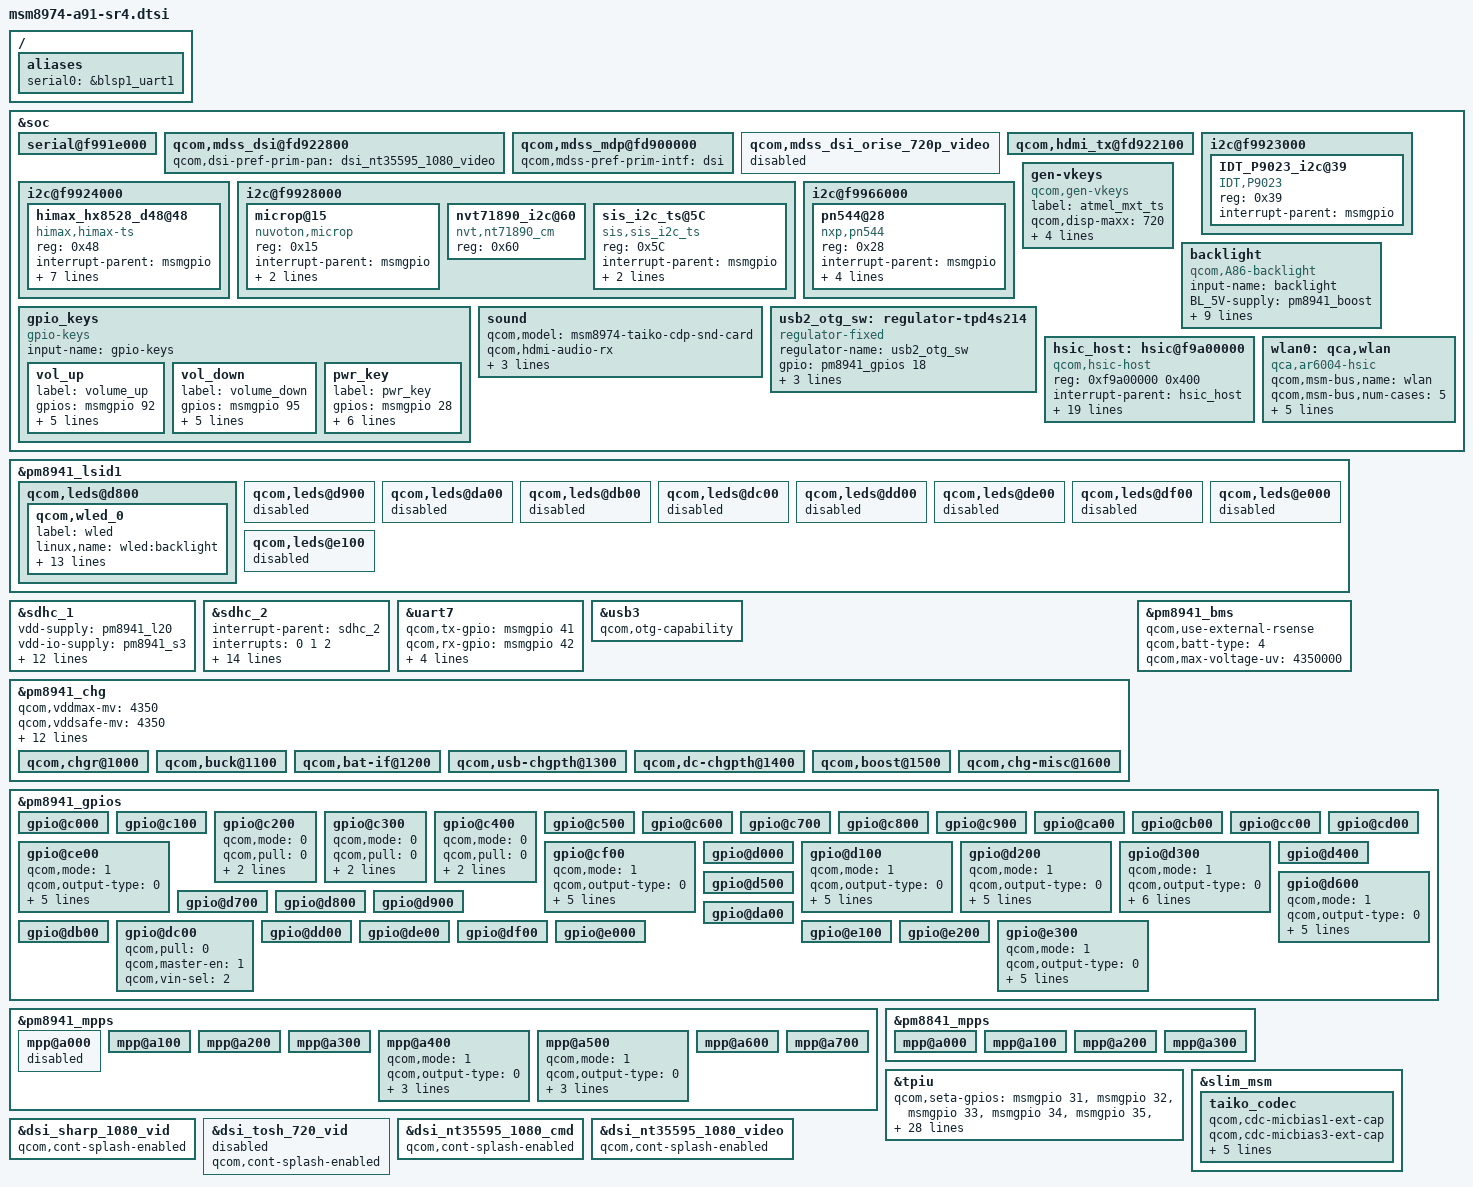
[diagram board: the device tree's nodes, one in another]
/* Copyright (c) 2012-2014, The Linux Foundation. All rights reserved.
 *
 * This program is free software; you can redistribute it and/or modify
 * it under the terms of the GNU General Public License version 2 and
 * only version 2 as published by the Free Software Foundation.
 *
 * This program is distributed in the hope that it will be useful,
 * but WITHOUT ANY WARRANTY; without even the implied warranty of
 * MERCHANTABILITY or FITNESS FOR A PARTICULAR PURPOSE.  See the
 * GNU General Public License for more details.
 */

//+++ ASUS_BSP : modify from msm8974-cdp.dtsi

#include "asus-common.dtsi"

/ {
	aliases {
		serial0 = &blsp1_uart1;
	};
};

&soc {
	serial@f991e000 {
		status = "ok";
	};

	qcom,mdss_dsi@fd922800 {
		qcom,dsi-pref-prim-pan = <&dsi_sharp_1080_vid>; // Add for ASUS Display driver 
		qcom,dsi-pref-prim-pan = <&dsi_nt35595_1080_cmd>; // Add for ASUS Innolux command mode driver 
        qcom,dsi-pref-prim-pan = <&dsi_nt35595_1080_video>;// Add for ASUS Innolux video mode driver 
	};

	qcom,mdss_mdp@fd900000 {
		qcom,mdss-pref-prim-intf = "dsi";
	};

	qcom,mdss_dsi_orise_720p_video {
		status = "disable";
	};

	qcom,hdmi_tx@fd922100 {
		status = "ok";
	};

// +++.....................................................I2C bus part....................................................+++//
//+++ ASUS BSP Eason......."BLSP1 : Wireless charger"
	i2c@f9923000 {
		IDT_P9023_i2c@39 {
			compatible = "IDT,P9023";
			reg = <0x39>;
			interrupt-parent = <&msmgpio>;
		};
	};
//--- ASUS BSP Eason......."BLSP1 : Wireless charger"

// +++ ASUS_BSP : add for ASUS touch 
	i2c@f9924000 {
		himax_hx8528_d48@48 {
			compatible = "himax,himax-ts";
			reg = <0x48>;
			interrupt-parent = <&msmgpio>;
			interrupts = <0 0x2>;
			vdd_ana-supply = <&pm8941_l23>;
			vcc_i2c-supply = <&pm8941_lvs1>;
			himax,reset-gpio = <&msmgpio 60 0x00>;
			himax,irq-gpio = <&msmgpio 0 0x00>;
			himax,pcb-id0 = <&msmgpio 69 0x00>;
			himax,pcb-id1 = <&msmgpio 90 0x00>;
		};
	};
// --- ASUS_BSP : add for ASUS touch 

// +++ ASUS BSP......."BLSP6 : Pad bus"
i2c@f9928000 {
		//+++ ASUS_BSP Eason +++
		microp@15 {
			compatible = "nuvoton,microp";
			reg = <0x15>;
			interrupt-parent = <&msmgpio>;
			interrupts = <9 0x2>;
			microp,irq-gpio = <&msmgpio 9 0x00>;
		};
		//--- ASUS_BSP Eason ---

		// ASUS_BSP +++ Louis, "Pad TCON control driver"
		nvt71890_i2c@60 {
			compatible = "nvt,nt71890_cm";
			reg = <0x60>;
		};
		// ASUS_BSP --- Louis, "Pad TCON control driver"

		// ASUS_BSP +++ SiS9257 Touch
		sis_i2c_ts@5C {
			compatible = "sis,sis_i2c_ts";
			reg = <0x5C>;
			interrupt-parent = <&msmgpio>;
			interrupts = <9 0x2>;
			sis_i2c_ts,irq-gpio = <&msmgpio 9 0x00>;
		};
		// ASUS_BSP --- SiS9257 Touch
	};
//--- ASUS BSP......."BLSP6 : Pad bus"

	//+++ ASUS BSP......."BLSP10 : NFC"
	i2c@f9966000 {
		//+++Porting NFC's kernel+++
		pn544@28 {
			//compatible = "nxp,nxp_pn544";
			compatible = "nxp,pn544";
			reg = <0x28>;
			interrupt-parent = <&msmgpio>;
			interrupts = <59 0x2>;
			nxp,irq-gpio = <&msmgpio 59 0x00>;
			nxp,nfc-ven = <&msmgpio 79 0x00>;
			nxp,download-gpio = <&pm8941_gpios 24 0x00>;
		};
		//---Porting NFC's kernel---
	};
	//--- ASUS BSP......."BLSP10 : NFC"

//---.....................................................I2C bus part....................................................---//

	gen-vkeys {
		compatible = "qcom,gen-vkeys";
		label = "atmel_mxt_ts";
		qcom,disp-maxx = <720>;
		qcom,disp-maxy = <1280>;
		qcom,panel-maxx = <760>;
		qcom,panel-maxy = <1424>;
		qcom,key-codes = <158 139 102 217>;
	};

//ASUS BSP freddy++ set gpio_keys	
	gpio_keys {
		compatible = "gpio-keys";
		input-name = "gpio-keys";

		vol_up {
			label = "volume_up";
			gpios = <&msmgpio 92 0x00>;
			interrupt-parent = <&msmgpio>;
			interrupts = <92 0x2>; 
			linux,input-type = <1>;
			linux,code = <115>;
			//gpio-key,wakeup;
			debounce-interval = <1>;
		};

		vol_down {
			label = "volume_down";
			gpios = <&msmgpio 95 0>;
			interrupt-parent = <&msmgpio>;
			interrupts = <95 0x2>;
			linux,input-type = <1>;
			linux,code = <114>;
			//gpio-key,wakeup;
			debounce-interval = <1>;
		};

	        pwr_key {
	            label = "pwr_key";
	            gpios = <&msmgpio 28 0x00>;
	            interrupt-parent = <&msmgpio>;
	            interrupts = <28 0x2>;
	            linux,input-type = <1>;
	            linux,code = <116>;
	            gpio-key,wakeup;
	            debounce-interval = <1>;
	        };
	};

	//ASUS BSP Jacob kung +++
	backlight {
		compatible = "qcom,A86-backlight";
		input-name = "backlight";
		BL_5V-supply = <&pm8941_boost>;
		pan-backlight-levels = <1 255>;
		bl-tout-defau-levels = <7 58>;
		normod-bl-param = <17 151 412>;
		outmod-bl-param = <58 255 340>;
		autmod-bl-param = <17 255 272>;
		factory-bl-param = <0 255 272>;
		pad-normod-bl-param = <0 250 240>;
		pad-outmod-bl-param = <33 255 557>;
		pad-autmod-bl-param = <9 255 448>;
		status = "okay";
	};
	//ASUS BSP Jacob kung +++
	sound {
		qcom,model = "msm8974-taiko-cdp-snd-card";
		qcom,hdmi-audio-rx;
		qcom,us-euro-gpios = <&pm8941_gpios 20 0>;
		qcom,cdc-micbias2-headset-only;
		qcom,mbhc-audio-jack-type = "6-pole-jack";
	};

	usb2_otg_sw: regulator-tpd4s214 {
		compatible = "regulator-fixed";
		regulator-name = "usb2_otg_sw";
		gpio = <&pm8941_gpios 18 0>;
		parent-supply = <&pm8941_boost>;
		startup-delay-us = <17000>;
		enable-active-high;
	};

	hsic_host: hsic@f9a00000 {
		compatible = "qcom,hsic-host";
		reg = <0xf9a00000 0x400>;
		#address-cells = <0>;
		interrupt-parent = <&hsic_host>;
		interrupts = <0 1 2>;
		#interrupt-cells = <1>;
		interrupt-map-mask = <0xffffffff>;
		interrupt-map = <0 &intc 0 136 0
			1 &intc 0 148 0
			2 &msmgpio 144 0x8>;
		interrupt-names = "core_irq", "async_irq", "wakeup";
		hsic_vdd_dig-supply = <&pm8841_s2_corner>;
		HSIC_GDSC-supply = <&gdsc_usb_hsic>;
		hsic,strobe-gpio = <&msmgpio 144 0x00>;
		hsic,data-gpio = <&msmgpio 145 0x00>;
		hsic,resume-gpio = <&msmgpio 80 0x00>;
		hsic,ignore-cal-pad-config;
		hsic,strobe-pad-offset = <0x2050>;
		hsic,data-pad-offset = <0x2054>;
		qcom,phy-susp-sof-workaround;
		hsic,vdd-voltage-level = <1 5 7>;

		qcom,msm-bus,name = "hsic";
		qcom,msm-bus,num-cases = <2>;
		qcom,msm-bus,num-paths = <1>;
		qcom,msm-bus,vectors-KBps =
				<85 512 0 0>,
				<85 512 40000 160000>;
        };

	wlan0: qca,wlan {
		compatible = "qca,ar6004-hsic";
		qcom,msm-bus,name = "wlan";
		qcom,msm-bus,num-cases = <5>;
		qcom,msm-bus,active-only = <0>;
		qcom,msm-bus,num-paths = <1>;
		qcom,msm-bus,vectors-KBps =
				<85 512 0 0>,
				<85 512 40000 160000>,
				<85 512 40000 320000>,
				<85 512 40000 480000>,
				<85 512 40000 800000>;
	};
};

&pm8941_lsid1 {
	qcom,leds@d800 {
		status = "okay";
		qcom,wled_0 {
			label = "wled";
			linux,name = "wled:backlight";
			linux,default-trigger = "bkl-trigger";
			qcom,cs-out-en;
			qcom,op-fdbck = <1>;
			qcom,default-state = "on";
			qcom,max-current = <20>;
			qcom,ctrl-delay-us = <0>;
			qcom,boost-curr-lim = <3>;
			qcom,cp-sel = <0>;
			qcom,switch-freq = <11>;
			qcom,ovp-val = <2>;
			qcom,num-strings = <2>;
			qcom,id = <0>;
			qcom,cabc-out-en = <1>;
		};
	};

	qcom,leds@d900 {
		status = "disabled";
	};

	qcom,leds@da00 {
		status = "disabled";
	};

	qcom,leds@db00 {
		status = "disabled";
	};

	qcom,leds@dc00 {
		status = "disabled";
	};

	qcom,leds@dd00 {
		status = "disabled";
	};

	qcom,leds@de00 {
		status = "disabled";
	};

	qcom,leds@df00 {
		status = "disabled";
	};

	qcom,leds@e000 {
		status = "disabled";
	};

	qcom,leds@e100 {
		status = "disabled";
	};
};

&sdhc_1 {
	vdd-supply = <&pm8941_l20>;
	vdd-io-supply = <&pm8941_s3>;

	qcom,vdd-always-on;
	qcom,vdd-lpm-sup;
	qcom,vdd-voltage-level = <2950000 2950000>;
	qcom,vdd-current-level = <800 500000>;

	qcom,vdd-io-always-on;
	qcom,vdd-io-voltage-level = <1800000 1800000>;
	qcom,vdd-io-current-level = <250 154000>;

	qcom,pad-pull-on = <0x0 0x3 0x3>; /* no-pull, pull-up, pull-up */
	qcom,pad-pull-off = <0x0 0x3 0x3>; /* no-pull, pull-up, pull-up */
	qcom,pad-drv-on = <0x4 0x4 0x4>; /* 10mA, 10mA, 10mA */
	qcom,pad-drv-off = <0x0 0x0 0x0>; /* 2mA, 2mA, 2mA */

	qcom,nonremovable;
	status = "ok";
};

&sdhc_2 {
	#address-cells = <0>;
	interrupt-parent = <&sdhc_2>;
	interrupts = <0 1 2>;
	#interrupt-cells = <1>;
	interrupt-map-mask = <0xffffffff>;
	interrupt-map = <0 &intc 0 125 0
			1 &intc 0 221 0
			2 &msmgpio 62 0x3>;
	interrupt-names = "hc_irq", "pwr_irq", "status_irq";
	cd-gpios = <&msmgpio 62 0x1>;

	vdd-supply = <&pm8941_l21>;
	vdd-io-supply = <&pm8941_l13>;

	qcom,vdd-voltage-level = <2950000 2950000>;
	qcom,vdd-current-level = <9000 800000>;

	qcom,vdd-io-voltage-level = <1800000 2950000>;
	qcom,vdd-io-current-level = <6 22000>;

	qcom,pad-pull-on = <0x0 0x3 0x3>; /* no-pull, pull-up, pull-up */
	qcom,pad-pull-off = <0x0 0x3 0x3>; /* no-pull, pull-up, pull-up */
	qcom,pad-drv-on = <0x4 0x4 0x4>; /* 10mA, 10mA, 10mA */
	qcom,pad-drv-off = <0x0 0x0 0x0>; /* 2mA, 2mA, 2mA */
	status = "ok";
};

&sdhc_1 {
	qcom,pad-drv-on = <0x7 0x4 0x4>; /* 16mA, 10mA, 10mA */
};

&sdhc_2 {
	qcom,pad-drv-on = <0x7 0x4 0x4>; /* 16mA, 10mA, 10mA */
};

&uart7 {
	status = "ok";
	qcom,tx-gpio = <&msmgpio 41 0x00>;
	qcom,rx-gpio = <&msmgpio 42 0x00>;
	qcom,cts-gpio = <&msmgpio 43 0x00>;
	qcom,rfr-gpio = <&msmgpio 44 0x00>;
	qcom,inject-rx-on-wakeup = <1>;
	qcom,rx-char-to-inject = <0xFD>;
};

&usb3 {
	qcom,otg-capability;
};

&pm8941_chg {
	status = "ok";
//ASUS_BSP Eason: add Power team charger setting+++
	qcom,vddmax-mv = <4350>;
	qcom,vddsafe-mv = <4350>;
	qcom,ibatmax-ma = <1100>;
	qcom,ibatterm-ma = <120>;
	qcom,ibatsafe-ma = <1100>;
	qcom,cool-bat-decidegc = <100>;
	qcom,cool-bat-mv = <4350>;
	qcom,ibatmax-warm-ma = <1100>;
	qcom,warm-bat-decidegc = <450>;
	qcom,warm-bat-mv = <4100>;
	qcom,ibatmax-cool-ma = <400>;
	qcom,vbatdet-delta-mv = <100>;
	qcom,maxinput-dc-ma = <300>;
	qcom,tchg-mins = <512>;
//ASUS_BSP Eason: add Power team charger setting---

	qcom,chgr@1000 {
		status = "ok";
	};

	qcom,buck@1100 {
		status = "ok";
	};

//ASUS_BSP Eason +++
	qcom,bat-if@1200 {
		status = "ok";
	};
//ASUS_BSP Eason ---

	qcom,usb-chgpth@1300 {
		status = "ok";
	};

	qcom,dc-chgpth@1400 {
		status = "ok";
	};

	qcom,boost@1500 {
		status = "ok";
	};

	qcom,chg-misc@1600 {
		status = "ok";
	};
};

//ASUS_BSP Eason: enable bms+++
&pm8941_bms {
	status = "ok";
	qcom,use-external-rsense;
	qcom,batt-type = <4>;
	qcom,max-voltage-uv = <4350000>;
};
//ASUS_BSP Eason: enable bms---

&pm8941_gpios {
	gpio@c000 { /* GPIO 1 */
	};

	gpio@c100 { /* GPIO 2 */
	};

	gpio@c200 { /* GPIO 3 */
		qcom,mode = <0>;
		qcom,pull = <0>;
		qcom,vin-sel = <2>;
		qcom,src-sel = <0>;
	};

	gpio@c300 { /* GPIO 4 */
		qcom,mode = <0>;
		qcom,pull = <0>;
		qcom,vin-sel = <2>;
		qcom,src-sel = <0>;
	};

	gpio@c400 { /* GPIO 5 */
		qcom,mode = <0>;
		qcom,pull = <0>;
		qcom,vin-sel = <2>;
		qcom,src-sel = <0>;
	};

	gpio@c500 { /* GPIO 6 */
	};

	gpio@c600 { /* GPIO 7 */
	};

	gpio@c700 { /* GPIO 8 */
	};

	gpio@c800 { /* GPIO 9 */
	};

	gpio@c900 { /* GPIO 10 */
	};

	gpio@ca00 { /* GPIO 11 */
	};

	gpio@cb00 { /* GPIO 12 */
	};

	gpio@cc00 { /* GPIO 13 */
	};

	gpio@cd00 { /* GPIO 14 */
	};

	gpio@ce00 { /* GPIO 15 */
		qcom,mode = <1>;
		qcom,output-type = <0>;
		qcom,pull = <5>;
		qcom,vin-sel = <2>;
		qcom,out-strength = <1>;
		qcom,src-sel = <2>;
		qcom,master-en = <1>;
	};

	gpio@cf00 { /* GPIO 16 */
		qcom,mode = <1>;
		qcom,output-type = <0>;
		qcom,pull = <2>;
		qcom,vin-sel = <2>;
		qcom,out-strength = <2>;
		qcom,src-sel = <2>;
		qcom,master-en = <1>;
	};

	gpio@d000 { /* GPIO 17 */
	};

	gpio@d100 { /* GPIO 18 */
		/* usb2_otg_sw regulator enable */
		qcom,mode = <1>;		/* Digital output */
		qcom,output-type = <0>;		/* CMOS logic */
		qcom,invert = <0>; 		/* Output low initially */
		qcom,vin-sel = <2>; 		/* PM8941 S3 = 1.8 V */
		qcom,src-sel = <0>; 		/* Constant */
		qcom,out-strength = <2>;	/* Medium drive strength */
		qcom,master-en = <1>;		/* Enable GPIO */
	};

	gpio@d200 { /* GPIO 19 */
		qcom,mode = <1>;		/* QPNP_PIN_MODE_DIG_OUT */
		qcom,output-type = <0>;		/* QPNP_PIN_OUT_BUF_CMOS */
		qcom,pull = <5>;		/* QPNP_PIN_PULL_NO */
		qcom,vin-sel = <2>;		/* QPNP_PIN_VIN2 */
		qcom,out-strength = <2>;	/* QPNP_PIN_OUT_STRENGTH_MED */
		qcom,src-sel = <0>;		/* QPNP_PIN_SEL_FUNC_CONSTANT */
		qcom,master-en = <1>;
	};

	gpio@d300 { /* GPIO 20 */
		qcom,mode = <1>;		/* QPNP_PIN_MODE_DIG_OUT */
		qcom,output-type = <0>;		/* QPNP_PIN_OUT_BUF_CMOS */
		qcom,invert = <0>; 		/* Output low initially */
		qcom,pull = <5>;		/* QPNP_PIN_PULL_NO */
		qcom,vin-sel = <2>;		/* QPNP_PIN_VIN2 */
		qcom,out-strength = <2>;	/* QPNP_PIN_OUT_STRENGTH_MED */
		qcom,src-sel = <0>;		/* QPNP_PIN_SEL_FUNC_CONSTANT */
		qcom,master-en = <1>;
	};

	gpio@d400 { /* GPIO 21 */
	};

	gpio@d500 { /* GPIO 22 */
	};

	gpio@d600 { /* GPIO 23 */
		qcom,mode = <1>;                /* QPNP_PIN_MODE_DIG_OUT */
		qcom,output-type = <0>;         /* QPNP_PIN_OUT_BUF_CMOS */
		qcom,pull = <5>;                /* QPNP_PIN_PULL_NO */
		qcom,vin-sel = <2>;             /* QPNP_PIN_VIN2 */
		qcom,out-strength = <2>;        /* QPNP_PIN_OUT_STRENGTH_MED */
		qcom,src-sel = <0>;             /* QPNP_PIN_SEL_FUNC_CONSTANT */
		qcom,master-en = <1>;
	};

	gpio@d700 { /* GPIO 24 */
	};

	gpio@d800 { /* GPIO 25 */
	};

	gpio@d900 { /* GPIO 26 */
	};

	gpio@da00 { /* GPIO 27 */
	};

	gpio@db00 { /* GPIO 28 */
	};

	gpio@dc00 { /* GPIO 29 */
		qcom,pull = <0>; /* set to default pull */
		qcom,master-en = <1>;
		qcom,vin-sel = <2>; /* select 1.8 V source */
	};

	gpio@dd00 { /* GPIO 30 */
	};

	gpio@de00 { /* GPIO 31 */
	};

	gpio@df00 { /* GPIO 32 */
	};

	gpio@e000 { /* GPIO 33 */
	};

	gpio@e100 { /* GPIO 34 */
	};

	gpio@e200 { /* GPIO 35 */
	};

	gpio@e300 { /* GPIO 36 */
		qcom,mode = <1>;  /* QPNP_PIN_MODE_DIG_OUT */
		qcom,output-type = <0>; /* QPNP_PIN_OUT_BUF_CMOS */
		qcom,pull = <5>; /* QPNP_PIN_PULL_NO */
		qcom,vin-sel = <2>; /* QPNP_PIN_VIN2 */
		qcom,out-strength = <3>; /* QPNP_PIN_OUT_STRENGTH_HIGH */
		qcom,src-sel = <3>; /* QPNP_PIN_SEL_FUNC_2 */
		qcom,master-en = <1>;
	};
};

&pm8941_mpps {

	mpp@a000 { /* MPP 1 */
		status = "disabled";
	};

	mpp@a100 { /* MPP 2 */
	};

	mpp@a200 { /* MPP 3 */
	};

	mpp@a300 { /* MPP 4 */
	};

	mpp@a400 { /* MPP 5 */
		/* SPI_ETH config */
		qcom,mode = <1>; /* DIG_OUT */
		qcom,output-type = <0>; /* CMOS */
		qcom,vin-sel = <2>; /* PM8941_S3 1.8V > 1.6V */
		qcom,src-sel = <0>; /* CONSTANT */
		qcom,master-en = <1>; /* ENABLE MPP */
	};

	mpp@a500 { /* MPP 6 */
		/* SPI_ETH_RST config */
		qcom,mode = <1>; /* DIG_OUT */
		qcom,output-type = <0>; /* CMOS */
		qcom,vin-sel = <2>; /* PM8941_S3 1.8V > 1.6V */
		qcom,src-sel = <0>; /* CONSTANT */
		qcom,master-en = <1>; /* ENABLE MPP */
	};

	mpp@a600 { /* MPP 7 */
	};

	mpp@a700 { /* MPP 8 */
	};
};

&pm8841_mpps {

	mpp@a000 { /* MPP 1 */
	};

	mpp@a100 { /* MPP 2 */
	};

	mpp@a200 { /* MPP 3 */
	};

	mpp@a300 { /* MPP 4 */
	};
};

/* CoreSight */
&tpiu {
	qcom,seta-gpios = <&msmgpio 31 0>,
			  <&msmgpio 32 0>,
			  <&msmgpio 33 0>,
			  <&msmgpio 34 0>,
			  <&msmgpio 35 0>,
			  <&msmgpio 36 0>,
			  <&msmgpio 37 0>,
			  <&msmgpio 38 0>,
			  <&msmgpio 39 0>,
			  <&msmgpio 40 0>,
			  <&msmgpio 41 0>,
			  <&msmgpio 42 0>,
			  <&msmgpio 43 0>,
			  <&msmgpio 44 0>,
			  <&msmgpio 45 0>,
			  <&msmgpio 46 0>,
			  <&msmgpio 47 0>,
			  <&msmgpio 48 0>;
	qcom,seta-gpios-func = <4 4 4 3 4 4 4 3 4 3 5 5 5 5 4 4 5 5>;
	qcom,seta-gpios-drv =  <7 7 7 7 7 7 7 7 7 7 7 7 7 7 7 7 7 7>;
	qcom,seta-gpios-pull = <0 0 0 0 0 0 0 0 0 0 0 0 0 0 0 0 0 0>;
	qcom,seta-gpios-dir =  <2 2 2 2 2 2 2 2 2 2 2 2 2 2 2 2 2 2>;

	qcom,setb-gpios = <&msmgpio 15 0>,
			  <&msmgpio 16 0>,
			  <&msmgpio 17 0>,
			  <&msmgpio 18 0>,
			  <&msmgpio 19 0>,
			  <&msmgpio 20 0>,
			  <&msmgpio 21 0>,
			  <&msmgpio 22 0>,
			  <&msmgpio 23 0>,
			  <&msmgpio 24 0>,
			  <&msmgpio 25 0>,
			  <&msmgpio 26 0>,
			  <&msmgpio 27 0>,
			  <&msmgpio 28 0>,
			  <&msmgpio 89 0>,
			  <&msmgpio 90 0>,
			  <&msmgpio 91 0>,
			  <&msmgpio 92 0>;
	qcom,setb-gpios-func = <2 2 2 2 5 5 5 5 6 6 6 7 7 5 2 3 3 3>;
	qcom,setb-gpios-drv =  <7 7 7 7 7 7 7 7 7 7 7 7 7 7 7 7 7 7>;
	qcom,setb-gpios-pull = <0 0 0 0 0 0 0 0 0 0 0 0 0 0 0 0 0 0>;
	qcom,setb-gpios-dir =  <2 2 2 2 2 2 2 2 2 2 2 2 2 2 2 2 2 2>;
};

&slim_msm {
	taiko_codec {
		qcom,cdc-micbias1-ext-cap;
		qcom,cdc-micbias3-ext-cap;
		qcom,cdc-micbias4-ext-cap;

		/* If boot isn't available, vph_pwr_vreg can be used instead */
		cdc-vdd-spkdrv-supply = <&pm8941_boost>;
		qcom,cdc-vdd-spkdrv-voltage = <5000000 5000000>;
		qcom,cdc-vdd-spkdrv-current = <1250000>;

		qcom,cdc-on-demand-supplies = "cdc-vdd-spkdrv";
	};
};

//ASUS_BSP: Louis, for A91 display +++
&dsi_sharp_1080_vid {
       status = "ok"; // Add for ASUS Display driver
       qcom,cont-splash-enabled;
};

&dsi_tosh_720_vid {
       status = "disable"; // Add for ASUS Display driver
       qcom,cont-splash-enabled;
};


&dsi_nt35595_1080_cmd {
	status = "ok";
	qcom,cont-splash-enabled;
};

&dsi_nt35595_1080_video {
	status = "ok";
	qcom,cont-splash-enabled;
};
//ASUS_BSP: Louis, for A91 display ---
